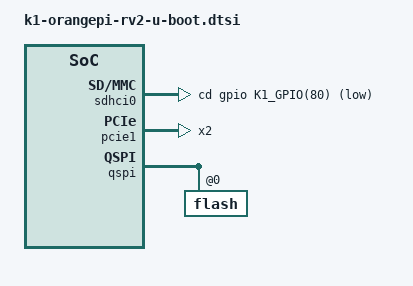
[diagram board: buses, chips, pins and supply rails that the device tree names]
// SPDX-License-Identifier: GPL-2.0-or-later OR MIT

#include "k1-orangepi-u-boot.dtsi"

&sdhci0 {
	cd-gpios = <&gpio K1_GPIO(80) (GPIO_ACTIVE_LOW | GPIO_PULL_UP)>;
	max-frequency = <204800000>;
	no-1-8-v;
	bootph-pre-ram;
};

/* Avoid gating the DBI clock while probing the bootloader PCIe host. */
&pcie1_3_cfg {
	pcie1-3-pins {
		pinmux = <K1_PADCONF(59, 4)>;
	};
};

&pcie2_4_cfg {
	pcie2-4-pins {
		pinmux = <K1_PADCONF(62, 4)>;
	};
};

&pcie1 {
	num-lanes = <2>;
};

&qspi {
	bootph-pre-ram;

	flash@0 {
		bootph-pre-ram;
	};
};

/* Retained initial single-rank DDR workarounds; removal is follow-up work. */
&{/soc} {
	dramc: ddr@c0000000 {
		compatible = "spacemit,k1-ddr";
		reg = <0x0 0xc0000000 0x0 0x400000>;
		datarate = <2400>;
		cs-num = <1>;
		type = "LPDDR4X";
		bootph-pre-ram;
	};
};
